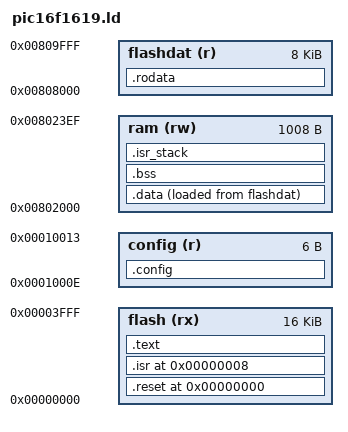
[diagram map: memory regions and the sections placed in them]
/* Linker script for the PIC16F1619.
 * Generated by tools/devdb/gen_toolchain.py from Microchip.PIC12-16F1xxx_DFP 1.10.270,
 * edc/PIC16F1619.PIC. Do not edit.
 *
 * Address spaces:
 *   0x000000 up   program memory, as byte addresses (two per 14-bit word)
 *   0x802000 up   RAM in the linear view the FSR registers use
 *   0x808000 up   flash read as data through an FSR, one byte per word
 */
/* Library variant: banks32 */
OUTPUT_FORMAT("elf32-pic16f1")
ENTRY(_start)

MEMORY
{
  flash    (rx) : ORIGIN = 0x000000, LENGTH = 0x4000
  ram      (rw) : ORIGIN = 0x802000, LENGTH = 1008
  flashdat (r)  : ORIGIN = 0x808000, LENGTH = 0x2000
  config   (r)  : ORIGIN = 0x1000e, LENGTH = 6
}

/* Bytes of stack for the interrupt handler, if there is one. */
PROVIDE(__isr_stack_size = 32);
/* Bytes kept for the main stack when a heap is in use. */
PROVIDE(__stack_size = 256);

SECTIONS
{
  /* Reset vector at word 0, interrupt vector at word 4. */
  .reset 0x0 : { KEEP(*(.reset)) } > flash
  .isr 0x8 : { KEEP(*(.isr)) } > flash
  .text : { *(.text .text.*) } > flash
  __text_end = .;

  /* Constants follow the code in flash. Their addresses are in the FSR
   * view: 0x8000 plus the word address, one byte in each word. */
  .rodata (ORIGIN(flashdat) + (__text_end + 1) / 2) :
  {
    *(.rodata .rodata.*)
  } > flashdat

  .data :
  {
    __data_start = .;
    *(.data .data.*)
    __data_end = .;
  } > ram AT> flashdat
  __data_load_start = LOADADDR(.data);
  __data_size = SIZEOF(.data);

  .bss (NOLOAD) :
  {
    __bss_start = .;
    *(.bss .bss.*)
    *(COMMON)
    __bss_end = .;
  } > ram
  __bss_size = SIZEOF(.bss);

  .isr_stack (NOLOAD) :
  {
    . += (SIZEOF(.isr) > 0) ? __isr_stack_size : 0;
    __isr_stack_top = .;
  } > ram

  /* The main stack grows down from the end of RAM. */
  __stack_top = ORIGIN(ram) + LENGTH(ram);

  /* malloc, if the program uses it, takes the RAM between the data and the
   * space set aside for the stack. Nothing enforces the boundary. */
  __heap_start = .;
  __heap_end = __stack_top - __stack_size;

  .config : { KEEP(*(.config)) } > config

  __flash_words_used = (__text_end + 1) / 2 + SIZEOF(.rodata) + SIZEOF(.data);
  ASSERT(__flash_words_used <= 8192, "program does not fit in flash")

  /DISCARD/ : { *(.note.GNU-stack) *(.comment) *(.eh_frame) *(.llvm_addrsig) }
}
